AUTOSAR XML (schema 4-2-2)
package /ARRoot
  sender receiver interface MyInterface
    data MyInterface: type=uint8
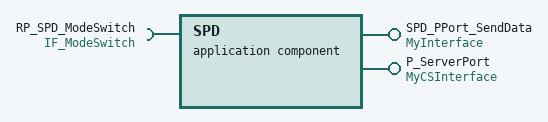
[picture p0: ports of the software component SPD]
  application sw component type SPD
    provide port SPD_PPort_SendData: nonqueued-sender-com-spec=data-element=MyInterface, provided-interface=MyInterface
    provide port P_ServerPort: provided-interface=MyCSInterface
    require port RP_SPD_ModeSwitch: mode-switch-receiver-com-spec{enhanced-mode-api=false, mode-group=TLT_MODE}, required-interface=IF_ModeSwitch
    swc-internal-behavior events={timing-event={start-on-event=SPD_Runnable, period=0.1}, operation-invoked-event=P_ServerPort.Operation1, operation-invoked-event=P_ServerPort.Operation2, swc-mode-switch-event={start-on-event=SPD_StartCallBk, activation=ON-ENTRY, mode=RP_SPD_ModeSwitch.TLT_MODE.Start}, swc-mode-switch-event={start-on-event=SPD_WaitCallBk, mode=RP_SPD_ModeSwitch.TLT_MODE.Wait}, swc-mode-switch-event={start-on-event=SPD_StopCallBk, mode=RP_SPD_ModeSwitch.TLT_MODE.Stop}}:
      4 x runnable:
        SPD_Runnable: data-send-points=variable-access=accessed-variable=SPD_PPort_SendData, mode-access-point=RP_SPD_ModeSwitch.TLT_MODE
        SPD_StartCallBk
        SPD_WaitCallBk
        SPD_StopCallBk
  swc-implementation behavior=/ARRoot/SPD/:
    code-descriptors:
      code Code
    resource consumption ResourceConsumption
  client server interface MyCSInterface
    operation Operation1: possible-error=E_OK
      arg Arg1: type=uint8, direction=IN
    operation Operation2: possible-error=E_OK
      arg Arg2: type=uint8, direction=OUT
    error E_OK
